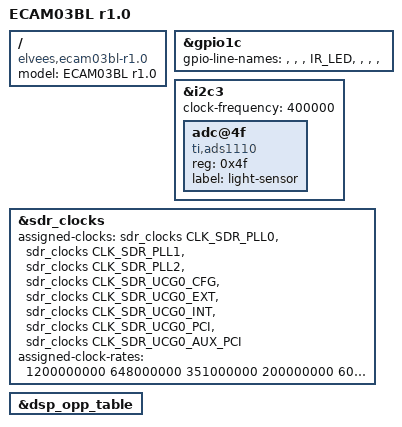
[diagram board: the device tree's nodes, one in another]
// SPDX-License-Identifier: GPL-2.0+
// Copyright 2021 RnD Center "ELVEES", JSC

/dts-v1/;

#include <dt-bindings/gpio/gpio.h>
#include <dt-bindings/input/input.h>

#include "mcom03-ecam03-common.dtsi"

/ {
	model = "ECAM03BL r1.0";
	compatible = "elvees,ecam03bl-r1.0",
		     "elvees,ecam03bl",
		     "elvees,mcom03";
};

/* IR_LED is named GPIO_S_PWR in schematics */
&gpio1c {
	gpio-line-names = "", "", "", "IR_LED", "", "", "", "";
};

&i2c3 {
	clock-frequency = <400000>;
	status = "okay";

	adc@4f {
		compatible = "ti,ads1110";
		reg = <0x4f>;
		label = "light-sensor";
	};
};

&sdr_clocks {
	assigned-clocks = <&sdr_clocks CLK_SDR_PLL0>,
			  <&sdr_clocks CLK_SDR_PLL1>,
			  <&sdr_clocks CLK_SDR_PLL2>,
			  <&sdr_clocks CLK_SDR_UCG0_CFG>,
			  <&sdr_clocks CLK_SDR_UCG0_EXT>,
			  <&sdr_clocks CLK_SDR_UCG0_INT>,
			  <&sdr_clocks CLK_SDR_UCG0_PCI>,
			  <&sdr_clocks CLK_SDR_UCG0_AUX_PCI>;
	assigned-clock-rates = <1200000000
				648000000
	/* PLL2 clock rate must match to one of the values
	 * described in dsp-opp-table.
	 */
				351000000
				200000000
				600000000
				400000000
				200000000
				50000000>;
};

&dsp_opp_table {
	/delete-node/ opp-405000000;
};
